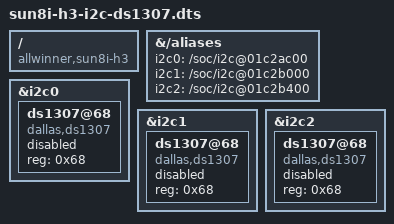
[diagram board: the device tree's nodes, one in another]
/dts-v1/ /plugin/;

/ {
	compatible = "allwinner,sun8i-h3";

	fragment@0 {
		target-path = "/aliases";
		__overlay__ {
			i2c0 = "/soc/i2c@01c2ac00";
			i2c1 = "/soc/i2c@01c2b000";
			i2c2 = "/soc/i2c@01c2b400";
		};
	};

	fragment@1 {
		target = <&i2c0>;
		__overlay__ {
			#address-cells = <1>;
			#size-cells = <0>;
			ds1307@68 {
				compatible = "dallas,ds1307";
				reg = <0x68>;
				status = "disabled";
			};
		};
	};

	fragment@2 {
		target = <&i2c1>;
		__overlay__ {
			#address-cells = <1>;
			#size-cells = <0>;
			ds1307@68 {
				compatible = "dallas,ds1307";
				reg = <0x68>;
				status = "disabled";
			};
		};
	};

	fragment@3 {
		target = <&i2c2>;
		__overlay__ {
			#address-cells = <1>;
			#size-cells = <0>;
			ds1307@68 {
				compatible = "dallas,ds1307";
				reg = <0x68>;
				status = "disabled";
			};
		};
	};
};
